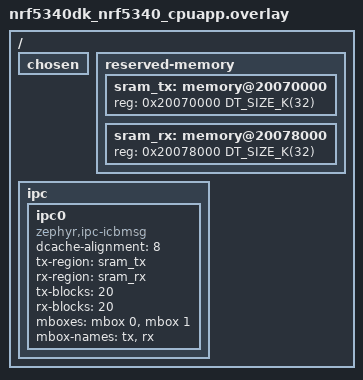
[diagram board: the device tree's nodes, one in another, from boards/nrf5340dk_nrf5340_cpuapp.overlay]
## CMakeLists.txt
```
# Copyright (c) 2026 Nordic Semiconductor ASA
# SPDX-License-Identifier: Apache-2.0

cmake_minimum_required(VERSION 3.28.0)
find_package(Zephyr REQUIRED HINTS $ENV{ZEPHYR_BASE})
project(log_ipc)

target_sources(app PRIVATE src/main.c src/mock_backend.c)
```

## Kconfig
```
# Copyright (c) 2026 Nordic Semiconductor ASA
# SPDX-License-Identifier: Apache-2.0

config TEST_LOG_IPC_EARLY_LOGS
	bool "Remote delivers logs created before IPC is bound"
	default y
	help
	  Set by sysbuild based on the remote configuration. When enabled, logs
	  created by the remote before the IPC endpoint is bound shall arrive.
	  When disabled, they shall be dropped and the drop shall be reported.

config TEST_LOG_IPC_BURST_CNT
	int "Number of messages in the burst test"
	default 20
	help
	  Set by sysbuild based on the remote configuration. IPC backend on the
	  remote sends each log message in a separate IPC buffer and drops
	  messages when there are no free buffers so burst must be smaller than
	  the number of IPC TX blocks.

source "Kconfig.zephyr"
```

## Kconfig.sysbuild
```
# Copyright (c) 2026 Nordic Semiconductor ASA
# SPDX-License-Identifier: Apache-2.0

config REMOTE_BOARD
	string
	default "$(BOARD)/nrf5340/cpunet" if BOARD_NRF5340DK_NRF5340_CPUAPP
	default "$(BOARD)/nrf5340/cpunet" if BOARD_NRF5340BSIM_NRF5340_CPUAPP
	default "$(BOARD)/nrf54l15/cpuflpr" if SOC_NRF54L15_CPUAPP

source "share/sysbuild/Kconfig"
```

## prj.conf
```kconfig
CONFIG_ZTEST=y
CONFIG_ASSERT=y
CONFIG_HEAP_MEM_POOL_SIZE=4096

CONFIG_IPC_SERVICE=y
CONFIG_MBOX=y

CONFIG_TEST_LOGGING_DEFAULTS=n
CONFIG_LOG=y
CONFIG_LOG_MODE_DEFERRED=y
CONFIG_LOG_BUFFER_SIZE=4096
CONFIG_LOG_MULTIDOMAIN=y
CONFIG_LOG_LINK_IPC=y
CONFIG_LOG_PRINTK=n
CONFIG_LOG_RUNTIME_FILTERING=n
CONFIG_IPC_SERVICE_LOG_LEVEL_OFF=y

# Mock backend is the only backend. It uses log_output for formatting.
CONFIG_LOG_OUTPUT=y
CONFIG_LOG_BACKEND_UART=n
CONFIG_LOG_BACKEND_NATIVE_POSIX=n
CONFIG_LOG_BACKEND_RTT=n

CONFIG_SHELL=y
CONFIG_SHELL_REMOTE=y
CONFIG_SHELL_BACKEND_DUMMY=y
CONFIG_SHELL_BACKEND_SERIAL=n
CONFIG_SHELL_LOG_BACKEND=n
CONFIG_SHELL_VT100_COLORS=n
CONFIG_SHELL_REMOTE_TIMEOUT_MS=1000
```

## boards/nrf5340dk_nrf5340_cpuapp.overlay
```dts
/*
 * Copyright (c) 2026 Nordic Semiconductor ASA
 *
 * SPDX-License-Identifier: Apache-2.0
 */

/delete-node/ &ipc0;
/delete-node/ &sram0_shared;

/ {
	chosen {
		/delete-property/ zephyr,ipc_shm;
		/delete-property/ zephyr,bt-hci;
	};

	reserved-memory {
		ranges;
		#address-cells = <1>;
		#size-cells = <1>;

		sram_tx: memory@20070000 {
			reg = <0x20070000 DT_SIZE_K(32)>;
		};

		sram_rx: memory@20078000 {
			reg = <0x20078000 DT_SIZE_K(32)>;
		};
	};

	ipc {
		ipc0: ipc0 {
			compatible = "zephyr,ipc-icbmsg";
			dcache-alignment = <8>;
			tx-region = <&sram_tx>;
			rx-region = <&sram_rx>;
			tx-blocks = <20>;
			rx-blocks = <20>;
			mboxes = <&mbox 0>, <&mbox 1>;
			mbox-names = "tx", "rx";
			status = "okay";
		};
	};
};
```

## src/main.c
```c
/*
 * Copyright (c) 2026 Nordic Semiconductor ASA
 *
 * SPDX-License-Identifier: Apache-2.0
 */

#include "mock_backend.h"
#include <zephyr/kernel.h>
#include <zephyr/ztest.h>
#include <zephyr/logging/log.h>
#include <zephyr/logging/log_ctrl.h>
#include <zephyr/logging/log_link.h>
#include <zephyr/shell/shell.h>
#include <zephyr/shell/shell_dummy.h>
#include <stdio.h>
#include <stdlib.h>
#include <string.h>

#define MODULE_NAME app
LOG_MODULE_REGISTER(MODULE_NAME, LOG_LEVEL_INF);

#ifndef CONFIG_LOG_RUNTIME_DEFAULT_LEVEL
#define CONFIG_LOG_RUNTIME_DEFAULT_LEVEL LOG_LEVEL_DBG
#endif

/* Must match the remote application. */
#define REMOTE_SOURCE_NAME "remote"
#define EARLY_LOG_CNT      3

#define LINK_ACTIVE_TIMEOUT_MS 5000
/* Logging thread may wait that long before processing pending messages. In the backend
 * configuration, messages are processed by logging threads on both cores (remote is assumed
 * to use the same sleep period).
 */
#define MSG_TIMEOUT_MS         (CONFIG_LOG_PROCESS_THREAD_SLEEP_MS + 100)
/* Remote and link report dropped messages with a delay (1 second each by default). */
#define DROPPED_TIMEOUT_MS     (MSG_TIMEOUT_MS + CONFIG_LOG_LINK_IPC_DROPPED_MSG_TIMEOUT)
#define POLL_MS                10

static const struct log_link *remote_link;
static uint8_t remote_domain;
static int16_t remote_source;

static int find_msg(size_t start, uint8_t domain_id, const char *text, bool exact,
		    struct mock_log_entry *entry)
{
	for (size_t i = start; i < mock_backend_count(); i++) {
		if (mock_backend_get(i, entry) && (entry->domain_id == domain_id) &&
		    (exact ? (strncmp(entry->text, text, strlen(text)) == 0) :
			     (strstr(entry->text, text) != NULL))) {
			return (int)i;
		}
	}

	return -1;
}

static int wait_msg(size_t start, uint8_t domain_id, const char *text, bool exact,
		    uint32_t timeout_ms, struct mock_log_entry *entry)
{
	int64_t end = k_uptime_get() + timeout_ms;
	int idx;

	do {
		idx = find_msg(start, domain_id, text, exact, entry);
		if (idx >= 0) {
			return idx;
		}
		k_msleep(POLL_MS);
	} while (k_uptime_get() < end);

	return -1;
}

static void print_captured(void)
{
	struct mock_log_entry entry;

	TC_PRINT("Captured messages (%zu):\n", mock_backend_count());
	for (size_t i = 0; i < mock_backend_count(); i++) {
		if (mock_backend_get(i, &entry)) {
			TC_PRINT("  [%zu] %s(%d)/%s(%d) lvl:%d \"%s\"\n", i, entry.domain,
				 entry.domain_id, entry.source, entry.source_id, entry.level,
				 entry.text);
		}
	}
}

/* Wait for a remote message and validate its origin and level. Returns the message index. */
static int expect_remote_msg(size_t start, const char *text, uint8_t level,
			     struct mock_log_entry *entry)
{
	struct mock_log_entry loc;
	int idx = wait_msg(start, remote_domain, text, true, MSG_TIMEOUT_MS, &loc);

	if (idx < 0) {
		print_captured();
	}
	zassert_true(idx >= 0, "Message \"%s\" not received", text);
	zassert_equal(loc.level, level, "Unexpected level %d for \"%s\"", loc.level, text);
	zassert_str_equal(loc.source, REMOTE_SOURCE_NAME);
	zassert_str_equal(loc.domain, remote_link->name);

	if (entry) {
		*entry = loc;
	}

	return idx;
}

/* Remote messages are processed in order so it must be called after a message which was
 * logged later on the remote has been received.
 */
static void expect_no_remote_msg(const char *text)
{
	struct mock_log_entry entry;

	zassert_true(find_msg(0, remote_domain, text, true, &entry) < 0,
		     "Unexpected message \"%s\": \"%s\"", text, entry.text);
}

static void remote_cmd(const char *cmd, bool check_output)
{
	const struct shell *sh = shell_backend_dummy_get_ptr();
	char buf[64];
	const char *out;
	size_t len;
	int err;

	snprintf(buf, sizeof(buf), "remote_shell %s", cmd);
	shell_backend_dummy_clear_output(sh);

	err = shell_execute_cmd(sh, buf);

	if (check_output) {
		zassert_equal(err, 0, "\"%s\" failed: %d", buf, err);

		out = shell_backend_dummy_get_output(sh, &len);
		zassert_not_null(strstr(out, "done"), "Unexpected \"%s\" output: \"%s\"", buf, out);
	}
}

static int16_t remote_source_id_get(void)
{
	uint32_t cnt = log_src_cnt_get(remote_domain);

	for (uint32_t i = 0; i < cnt; i++) {
		const char *name = log_source_name_get(remote_domain, i);

		if ((name != NULL) && (strcmp(name, REMOTE_SOURCE_NAME) == 0)) {
			return (int16_t)i;
		}
	}

	return -1;
}

static int remote_level_set(uint32_t level)
{
	return log_filter_set(mock_backend_get_instance(), remote_domain, remote_source, level);
}

static int remote_level_get(bool runtime)
{
	return log_filter_get(mock_backend_get_instance(), remote_domain, remote_source, runtime);
}

/* 00 in name to ensure that it runs first. */
ZTEST(log_ipc, test_00_early_logs)
{
	char text[32];
	int idx = 0;

	if (!IS_ENABLED(CONFIG_TEST_LOG_IPC_EARLY_LOGS)) {
		unsigned long dropped;
		struct mock_log_entry entry;

		snprintf(text, sizeof(text), "Remote: %s dropped messages: ", remote_link->name);
		idx = wait_msg(0, Z_LOG_LOCAL_DOMAIN_ID, text, true, DROPPED_TIMEOUT_MS, &entry);
		if (idx < 0) {
			print_captured();
		}
		zassert_true(idx >= 0, "No report about dropped early messages");

		dropped = strtoul(&entry.text[strlen(text)], NULL, 10);
		zassert_true(dropped >= EARLY_LOG_CNT, "Unexpected dropped count: %lu", dropped);

		zassert_true(find_msg(0, remote_domain, "early", true, &entry) < 0,
			     "Unexpected early message \"%s\"", entry.text);
		return;
	}

	for (int i = 0; i < EARLY_LOG_CNT; i++) {
		snprintf(text, sizeof(text), "early %d/%d", i, EARLY_LOG_CNT);
		idx = expect_remote_msg(idx, text, LOG_LEVEL_INF, NULL) + 1;
	}
}

ZTEST(log_ipc, test_local_message)
{
	struct mock_log_entry entry;
	int idx;

	mock_backend_reset();
	LOG_INF("local message");
	idx = wait_msg(0, Z_LOG_LOCAL_DOMAIN_ID, "local message", true, MSG_TIMEOUT_MS, &entry);

	zassert_true(idx >= 0);
	zassert_str_equal(entry.domain, CONFIG_LOG_DOMAIN_NAME);
	zassert_str_equal(entry.source, STRINGIFY(MODULE_NAME));
}

ZTEST(log_ipc, test_remote_various_msg_types)
{
	int idx = 0;
	struct mock_log_entry entry;

	mock_backend_reset();
	remote_cmd("log_gen levels", true);

	idx = expect_remote_msg(idx, "lvl err -1", LOG_LEVEL_ERR, NULL) + 1;
	idx = expect_remote_msg(idx, "lvl wrn ro_str", LOG_LEVEL_WRN, NULL) + 1;
	idx = expect_remote_msg(idx, "lvl inf rw_str", LOG_LEVEL_INF, NULL) + 1;
	idx = expect_remote_msg(idx, "lvl dbg 100 78187493520", LOG_LEVEL_DBG, NULL) + 1;
	idx = expect_remote_msg(idx, "lvl hexdump", LOG_LEVEL_INF, &entry) + 1;
	zassert_not_null(strstr(entry.text, "de ad be ef 01 02 03 04"),
			 "Unexpected hexdump: \"%s\"", entry.text);
	(void)expect_remote_msg(idx, "lvl end", LOG_LEVEL_ERR, NULL);
}

ZTEST(log_ipc, test_remote_runtime_filtering)
{
	Z_TEST_SKIP_IFNDEF(CONFIG_LOG_RUNTIME_FILTERING);

	zassert_equal(remote_level_get(false), LOG_LEVEL_DBG);
	zassert_equal(remote_level_get(true), CONFIG_LOG_RUNTIME_DEFAULT_LEVEL);

	zassert_equal(remote_level_set(LOG_LEVEL_WRN), LOG_LEVEL_WRN);
	zassert_equal(remote_level_get(true), LOG_LEVEL_WRN);

	mock_backend_reset();
	remote_cmd("log_gen levels", true);

	expect_remote_msg(0, "lvl err", LOG_LEVEL_ERR, NULL);
	expect_remote_msg(0, "lvl wrn", LOG_LEVEL_WRN, NULL);
	expect_remote_msg(0, "lvl end", LOG_LEVEL_ERR, NULL);
	expect_no_remote_msg("lvl inf");
	expect_no_remote_msg("lvl dbg");
	expect_no_remote_msg("lvl hexdump");

	zassert_equal(remote_level_set(LOG_LEVEL_DBG), LOG_LEVEL_DBG);
	zassert_equal(remote_level_get(true), LOG_LEVEL_DBG);

	mock_backend_reset();
	remote_cmd("log_gen levels", true);

	expect_remote_msg(0, "lvl inf", LOG_LEVEL_INF, NULL);
	expect_remote_msg(0, "lvl dbg", LOG_LEVEL_DBG, NULL);
}

ZTEST(log_ipc, test_remote_burst)
{
	struct mock_log_entry entry;
	char text[32];
	int idx = 0;

	mock_backend_reset();
	remote_cmd("log_gen burst " STRINGIFY(CONFIG_TEST_LOG_IPC_BURST_CNT), true);

	for (int i = 0; i < CONFIG_TEST_LOG_IPC_BURST_CNT; i++) {
		snprintf(text, sizeof(text), "burst %d", i);
		idx = expect_remote_msg(idx, text, LOG_LEVEL_INF, &entry) + 1;
	}

	zassert_equal(mock_backend_dropped(), 0);
	zassert_true(find_msg(0, Z_LOG_LOCAL_DOMAIN_ID, "Remote:", true, &entry) < 0,
		     "Unexpected message \"%s\"", entry.text);
}

ZTEST(log_ipc, test_remote_burst_dropped)
{
#define TOTAL_MSGS 100
	struct mock_log_entry entry;
	uint32_t received_msgs = 0;
	uint32_t dropped_msgs;
	int idx = 0;

	mock_backend_reset();
	remote_cmd("log_gen burst " STRINGIFY(TOTAL_MSGS), true);

	/* Wait for all remote messages to arrive. */
	k_msleep(DROPPED_TIMEOUT_MS + 1000);

	do {
		idx = find_msg(idx, remote_domain, "burst", true, &entry);
		if (idx < 0) {
			break;
		}
		received_msgs++;
		idx++;
	} while (received_msgs < TOTAL_MSGS);

	if (received_msgs < 10) {
		print_captured();
	}
	dropped_msgs = mock_backend_dropped();
	zassert_equal(received_msgs + dropped_msgs, TOTAL_MSGS, "Unexpected total count: %d",
		      received_msgs + dropped_msgs);

	if (!IS_ENABLED(CONFIG_LOG_LINK_IPC_RX_HOLD)) {
		/* If RX hold is not used, then local mpsc packet buffer is used so messages are
		 * dropped when the local buffer is full and there is no additionalwarning.
		 */
		return;
	}

	if (dropped_msgs > 0) {
		/* Find dropped message warning. */
		char text[64];

		snprintf(text, sizeof(text), "Remote: %s dropped messages: ", remote_link->name);
		zassert_true(find_msg(0, Z_LOG_LOCAL_DOMAIN_ID, text, true, &entry) >= 0,
			     "Unexpected message \"%s\"", text);
	}
}

ZTEST(log_ipc, test_remote_z_panic_report)
{
	struct mock_log_entry entry;
	int idx;

	Z_TEST_SKIP_IFDEF(IS_ENABLED(CONFIG_ARCH_POSIX));

	mock_backend_reset();
	remote_cmd("panic", false);

	idx = wait_msg(0, remote_domain, ">>> ZEPHYR FATAL ERROR", false, MSG_TIMEOUT_MS, &entry);
	if (idx < 0) {
		print_captured();
	}

	zassert_true(idx >= 0, "Remote panic report \"%s\" not received",
		     ">>> ZEPHYR FATAL ERROR");
	zassert_equal(entry.level, LOG_LEVEL_ERR, "Unexpected level %d for panic report",
		      entry.level);

	idx = wait_msg(0, remote_domain, "Kernel panic", false, MSG_TIMEOUT_MS, &entry);
	if (idx < 0) {
		print_captured();
	}

	zassert_true(idx >= 0, "Remote panic reason \"%s\" not received",
		     "Kernel panic");
	zassert_equal(entry.level, LOG_LEVEL_ERR, "Unexpected level %d for panic reason",
		      entry.level);
}

static void *log_ipc_setup(void)
{
	const struct shell *sh = shell_backend_dummy_get_ptr();
	int64_t end = k_uptime_get() + LINK_ACTIVE_TIMEOUT_MS;

	STRUCT_SECTION_GET(log_link, 0, &remote_link);

	/* Domain ID is assigned by the logging thread when the link is activated. */
	while ((remote_link->ctrl_blk->domain_offset == 0) && (k_uptime_get() < end)) {
		k_msleep(POLL_MS);
	}
	zassert_not_equal(remote_link->ctrl_blk->domain_offset, 0, "Link not activated");
	remote_domain = remote_link->ctrl_blk->domain_offset;
	zassert_not_equal(remote_domain, Z_LOG_LOCAL_DOMAIN_ID);
	zassert_str_equal(log_domain_name_get(remote_domain), remote_link->name);
	remote_source = remote_source_id_get();
	zassert_true(remote_source >= 0, "Remote source \"%s\" not found", REMOTE_SOURCE_NAME);

#if defined(CONFIG_LOG_RUNTIME_FILTERING)
	/* After activation, the logging thread sets runtime levels of all remote sources. */
	while ((remote_level_get(true) != CONFIG_LOG_RUNTIME_DEFAULT_LEVEL) &&
	       (k_uptime_get() < end)) {
		k_msleep(POLL_MS);
	}
#endif

	while (!shell_ready(sh) && (k_uptime_get() < end)) {
		k_msleep(POLL_MS);
	}
	zassert_true(shell_ready(sh), "Dummy shell not ready");

	TC_PRINT("Remote domain %s (id:%d), sources:%d\n", remote_link->name, remote_domain,
		 log_src_cnt_get(remote_domain));

	return NULL;
}

ZTEST_SUITE(log_ipc, NULL, log_ipc_setup, NULL, NULL, NULL);
```

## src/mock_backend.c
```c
/*
 * Copyright (c) 2026 Nordic Semiconductor ASA
 *
 * SPDX-License-Identifier: Apache-2.0
 */

#include "mock_backend.h"
#include <zephyr/kernel.h>
#include <zephyr/logging/log_ctrl.h>
#include <zephyr/logging/log_output.h>
#include <string.h>

#define MOCK_ENTRY_CNT 100

static struct mock_log_entry entries[MOCK_ENTRY_CNT];
/* Total number of messages captured since reset. Only the last MOCK_ENTRY_CNT are kept. */
static size_t entry_cnt;
static size_t text_len;
static atomic_t dropped;
static struct k_spinlock lock;

static int char_out(uint8_t *data, size_t length, void *ctx)
{
	struct mock_log_entry *entry = &entries[entry_cnt % MOCK_ENTRY_CNT];

	ARG_UNUSED(ctx);

	for (size_t i = 0; i < length; i++) {
		if (text_len < (sizeof(entry->text) - 1)) {
			entry->text[text_len++] = data[i];
		}
	}

	return length;
}

static uint8_t mock_output_buf[16];
LOG_OUTPUT_DEFINE(log_output_mock, char_out, mock_output_buf, sizeof(mock_output_buf));

static void copy_name(char *dst, const char *name)
{
	if (name == NULL) {
		dst[0] = '\0';
		return;
	}

	strncpy(dst, name, MOCK_ENTRY_NAME_LEN - 1);
	dst[MOCK_ENTRY_NAME_LEN - 1] = '\0';
}

static void process(const struct log_backend *const backend, union log_msg_generic *msg)
{
	struct log_msg *log_msg = &msg->log;
	struct mock_log_entry *entry = &entries[entry_cnt % MOCK_ENTRY_CNT];
	size_t plen, dlen;
	uint8_t *package = log_msg_get_package(log_msg, &plen);
	uint8_t *data = log_msg_get_data(log_msg, &dlen);
	k_spinlock_key_t key;

	ARG_UNUSED(backend);

	memset(entry, 0, sizeof(*entry));
	entry->domain_id = log_msg_get_domain(log_msg);
	entry->source_id = log_msg_get_source_id(log_msg);
	entry->level = log_msg_get_level(log_msg);
	copy_name(entry->domain, log_domain_name_get(entry->domain_id));
	copy_name(entry->source, entry->source_id >= 0
					 ? log_source_name_get(entry->domain_id, entry->source_id)
					 : NULL);

	/* Only the message body is rendered, prefix is captured in dedicated fields. */
	text_len = 0;
	log_output_process(&log_output_mock, 0, NULL, NULL, NULL, 0, entry->level,
			   plen > 0 ? package : NULL, data, dlen, LOG_OUTPUT_FLAG_CRLF_NONE);

	while ((text_len > 0) &&
	       ((entry->text[text_len - 1] == '\n') || (entry->text[text_len - 1] == '\r'))) {
		text_len--;
	}
	entry->text[text_len] = '\0';

	key = k_spin_lock(&lock);
	entry_cnt++;
	k_spin_unlock(&lock, key);
}

static void dropped_cb(const struct log_backend *const backend, uint32_t cnt)
{
	ARG_UNUSED(backend);

	atomic_add(&dropped, cnt);
}

static void panic(const struct log_backend *const backend)
{
	ARG_UNUSED(backend);
}

void mock_backend_reset(void)
{
	k_spinlock_key_t key = k_spin_lock(&lock);

	entry_cnt = 0;
	atomic_set(&dropped, 0);
	k_spin_unlock(&lock, key);
}

size_t mock_backend_count(void)
{
	return entry_cnt;
}

bool mock_backend_get(size_t idx, struct mock_log_entry *entry)
{
	k_spinlock_key_t key = k_spin_lock(&lock);
	bool rv = (idx < entry_cnt) && ((entry_cnt - idx) <= MOCK_ENTRY_CNT);

	if (rv) {
		*entry = entries[idx % MOCK_ENTRY_CNT];
	}
	k_spin_unlock(&lock, key);

	return rv;
}

uint32_t mock_backend_dropped(void)
{
	return (uint32_t)atomic_get(&dropped);
}

static const struct log_backend_api mock_log_backend_api = {
	.process = process,
	.dropped = dropped_cb,
	.panic = panic,
};

LOG_BACKEND_DEFINE(log_backend_mock, mock_log_backend_api, true);

const struct log_backend *mock_backend_get_instance(void)
{
	return &log_backend_mock;
}
```

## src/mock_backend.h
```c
/*
 * Copyright (c) 2026 Nordic Semiconductor ASA
 *
 * SPDX-License-Identifier: Apache-2.0
 */

#ifndef SRC_MOCK_BACKEND_H__
#define SRC_MOCK_BACKEND_H__

#include <zephyr/logging/log_backend.h>

#ifdef __cplusplus
extern "C" {
#endif

#define MOCK_ENTRY_TEXT_LEN 96
#define MOCK_ENTRY_NAME_LEN 24

/** @brief Captured log message. */
struct mock_log_entry {
	uint8_t domain_id;
	int16_t source_id;
	uint8_t level;
	char domain[MOCK_ENTRY_NAME_LEN];
	char source[MOCK_ENTRY_NAME_LEN];
	/* Formatted message without prefix and trailing new line. Hexdump included. */
	char text[MOCK_ENTRY_TEXT_LEN];
};

/** @brief Get the mock backend instance. */
const struct log_backend *mock_backend_get_instance(void);

/** @brief Remove all captured messages. */
void mock_backend_reset(void);

/** @brief Get number of messages captured since the last reset. */
size_t mock_backend_count(void);

/** @brief Get a copy of the captured message.
 *
 * @param idx Message index (0 is the oldest one).
 * @param entry Location where message is copied.
 *
 * @retval true if message exists.
 */
bool mock_backend_get(size_t idx, struct mock_log_entry *entry);

/** @brief Get number of messages reported as dropped by the logging core. */
uint32_t mock_backend_dropped(void);

#ifdef __cplusplus
}
#endif

#endif /* SRC_MOCK_BACKEND_H__ */
```
